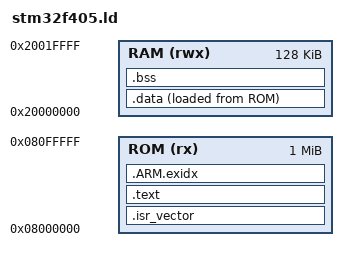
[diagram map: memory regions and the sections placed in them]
MEMORY
{
    ROM (rx)  : ORIGIN = 0x08000000, LENGTH = 1024K
    RAM (rwx) : ORIGIN = 0x20000000, LENGTH = 128K
}

ENTRY(Reset_Handler)

_stack_top = ORIGIN(RAM) + LENGTH(RAM);

PHDRS
{
    text PT_LOAD FLAGS(5);
    data PT_LOAD FLAGS(6);
}

SECTIONS
{
    .isr_vector :
    {
        . = ALIGN(4);
        KEEP(*(.isr_vector))
        . = ALIGN(4);
    } > ROM :text

    .text :
    {
        . = ALIGN(4);
        *(.text)
        *(.text*)
        *(.rodata)
        *(.rodata*)
        *(.glue_7)
        *(.glue_7t)
        *(.eh_frame)
        . = ALIGN(4);
    } > ROM :text

    .ARM.exidx :
    {
        . = ALIGN(4);
        *(.ARM.exidx*)
        . = ALIGN(4);
    } > ROM :text

    .data :
    {
        . = ALIGN(4);
        _sdata = .;
        *(.data)
        *(.data*)
        . = ALIGN(4);
        _edata = .;
    } > RAM AT > ROM :data

    _sidata = LOADADDR(.data);

    .bss (NOLOAD) :
    {
        . = ALIGN(4);
        _sbss = .;
        *(.bss)
        *(.bss*)
        *(COMMON)
        . = ALIGN(4);
        _ebss = .;
    } > RAM :data
}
